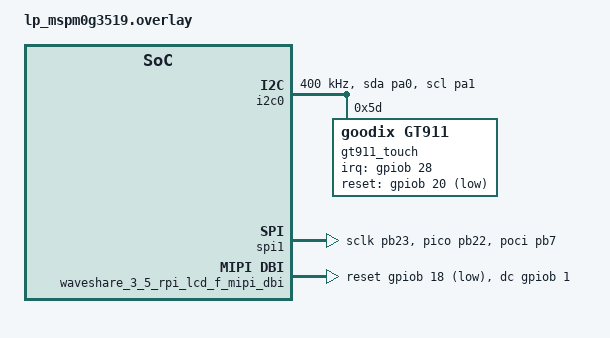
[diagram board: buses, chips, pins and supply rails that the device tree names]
/*
 * SPDX-FileCopyrightText: 2026 Texas Instruments Incorporated
 * SPDX-License-Identifier: Apache-2.0
 */

#include <zephyr/dt-bindings/i2c/i2c.h>

&i2c0 {
	pinctrl-0 = <&i2c0_sda_pa0 &i2c0_scl_pa1>;
	pinctrl-names = "default";
	clock-frequency = <I2C_BITRATE_FAST>;
	status = "okay";

	gt911_touch: gt911@5d {
		compatible = "goodix,gt911";
		reg = <0x5d>;
		alt-addr = <0x14>;
		irq-gpios = <&gpiob 28 GPIO_ACTIVE_HIGH>;
		reset-gpios = <&gpiob 20 GPIO_ACTIVE_LOW>;
		screen-width = <320>;
		screen-height = <480>;
	};
};

&spi1 {
	pinctrl-0 = <&spi1_sclk_pb23 &spi1_pico_pb22 &spi1_poci_pb7>;
	cs-gpios = <&gpioa 18 GPIO_ACTIVE_LOW>;
	status = "okay";
};

&waveshare_3_5_rpi_lcd_f_mipi_dbi {
	dc-gpios = <&gpiob 1 GPIO_ACTIVE_HIGH>;
	reset-gpios = <&gpiob 18 GPIO_ACTIVE_LOW>;
	spi-dev = <&spi1>;
};

&st7796s_display {
	mipi-max-frequency = <40000000>;
};
